# ATSAM3XxE register map
Vendor: Atmel; Series: SAM3X; File version: 0
Atmel ATSAM3XxE Microcontroller
CPU: CM3 r2p0, selectable endian, MPU, no FPU, 4 interrupt priority bits
Registers are 32-bit, read-write, reset 0x0 unless marked. A register's access mark holds for its fields unless they carry their own. Offsets are from the block's base; lines under a group give offsets from that group; [hi:lo] are bit positions; {n}, {i} and the like mark numbered series; 'fields as' and 'values as' point back to an identical list; <NAME> marks a mode.

## Memory map
0x40000000 HSMCI size 0x4000 — High Speed MultiMedia Card Interface
0x40004000 SSC size 0x4000 — Synchronous Serial Controller
0x40008000 SPI0 size 0x4000 — Serial Peripheral Interface 0
0x4000D000 MPU size 0x830 — Memory Protection Unit (MPU)
0x40080000 TC0 size 0x4000 — Timer Counter 0
0x40084000 TC1 size 0x4000 — Timer Counter 1
0x40088000 TC2 size 0x4000 — Timer Counter 2
0x4008C000 TWI0 size 0x4000 — Two-wire Interface 0
0x40090000 TWI1 size 0x4000 — Two-wire Interface 1
0x40094000 PWM size 0x4000 — Pulse Width Modulation Controller
0x40098000 USART0 size 0x4000 — Universal Synchronous Asynchronous Receiver Transmitter 0
0x4009C000 USART1 size 0x4000 — Universal Synchronous Asynchronous Receiver Transmitter 1
0x400A0000 USART2 size 0x4000 — Universal Synchronous Asynchronous Receiver Transmitter 2
0x400A4000 USART3 size 0x4000 — Universal Synchronous Asynchronous Receiver Transmitter 3
0x400AC000 UOTGHS size 0x4000 — USB On-The-Go Interface
0x400B0000 EMAC size 0x4000 — Ethernet MAC 10/100
0x400B4000 CAN0 size 0x4000 — Controller Area Network 0
0x400B8000 CAN1 size 0x4000 — Controller Area Network 1
0x400BC000 TRNG size 0x4000 — True Random Number Generator
0x400C0000 ADC size 0x4000 — Analog-to-Digital Converter
0x400C4000 DMAC size 0x4000 — DMA Controller
0x400C8000 DACC size 0x4000 — Digital-to-Analog Converter Controller
0x400E0000 SMC size 0x200 — Static Memory Controller
0x400E0400 MATRIX size 0x200 — AHB Bus Matrix
0x400E0600 PMC size 0x140 — Power Management Controller
0x400E0800 UART size 0x128 — Universal Asynchronous Receiver Transmitter
0x400E0940 CHIPID size 0x200 — Chip Identifier
0x400E0A00 EFC0 size 0x200 — Embedded Flash Controller 0
0x400E0C00 EFC1 size 0x200 — Embedded Flash Controller 1
0x400E0E00 PIOA size 0x200 — Parallel Input/Output Controller A
0x400E1000 PIOB size 0x200 — Parallel Input/Output Controller B
0x400E1200 PIOC size 0x200 — Parallel Input/Output Controller C
0x400E1400 PIOD size 0x200 — Parallel Input/Output Controller D
0x400E1A00 RSTC size 0x10 — Reset Controller
0x400E1A10 SUPC size 0x18 — Supply Controller
0x400E1A30 RTT size 0x10 — Real-time Timer
0x400E1A50 WDT size 0x10 — Watchdog Timer
0x400E1A60 RTC size 0xE8 — Real-time Clock
0x400E1A90 GPBR size 0x20 — General Purpose Backup Registers
0xE000E000 SCB blocks up to offset 0xD40 — System Control Block (SCB)
0xE000E010 SYST size 0x10 — System timer, SysTick
0xE000E100 NVIC size 0xE04 — Nested Vectored Interrupt Controller (NVIC)

## Interrupts
3 INT_Hard_Fault (SCB)
4 INT_Mem_Manage_Fault (SCB)
5 INT_Bus_Fault (SCB)
5 PMC
6 EFC0
6 INT_Usage_Fault (SCB)
7 EFC1
8 UART
11 INT_SVCall (SCB)
11 PIOA
12 PIOB
13 PIOC
14 INT_PendableSrvReq (SCB)
14 PIOD
15 INT_SysTick (SYST)
17 USART0
18 USART1
19 USART2
20 USART3
21 HSMCI
22 TWI0
23 TWI1
24 SPI0
26 SSC
27 TC0
28 TC1 (TC0)
29 TC2 (TC0)
30 TC3 (TC1)
31 TC4 (TC1)
32 TC5 (TC1)
33 TC6 (TC2)
34 TC7 (TC2)
35 TC8 (TC2)
36 PWM
37 ADC
38 DACC
39 DMAC
40 UOTGHS
41 TRNG
42 EMAC
43 CAN0
44 CAN1

## SPI0 — Serial Peripheral Interface 0
Base 0x40008000; register names take the prefix SPI0_
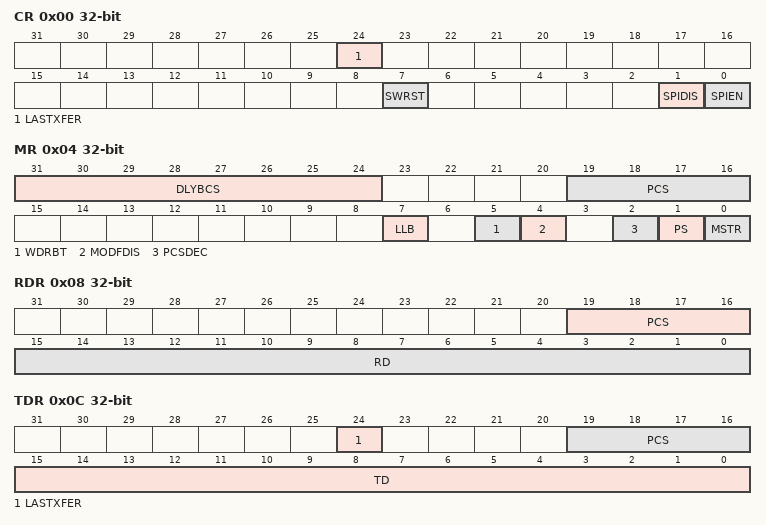
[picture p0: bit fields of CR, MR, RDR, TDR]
0x00 CR wo reset not defined — Control Register
  [24] LASTXFER — Last Transfer
  [7] SWRST — SPI Software Reset
  [1] SPIDIS — SPI Disable
  [0] SPIEN — SPI Enable
0x04 MR — Mode Register
  [31:24] DLYBCS — Delay Between Chip Selects
  [19:16] PCS — Peripheral Chip Select
  [7] LLB — Local Loopback Enable
  [5] WDRBT — Wait Data Read Before Transfer
  [4] MODFDIS — Mode Fault Detection
  [2] PCSDEC — Chip Select Decode
  [1] PS — Peripheral Select
  [0] MSTR — Master/Slave Mode
0x08 RDR ro — Receive Data Register
  [19:16] PCS — Peripheral Chip Select
  [15:0] RD — Receive Data
0x0C TDR wo reset not defined — Transmit Data Register
  [24] LASTXFER — Last Transfer
  [19:16] PCS — Peripheral Chip Select
  [15:0] TD — Transmit Data
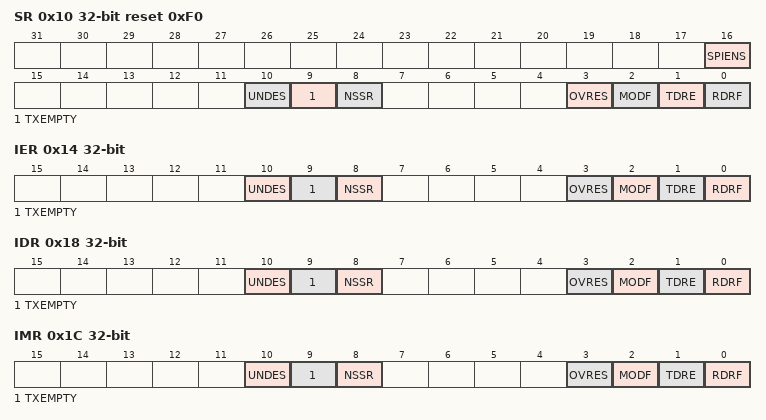
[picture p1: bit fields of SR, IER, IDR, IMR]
0x10 SR ro reset 0xF0 — Status Register
  [16] SPIENS — SPI Enable Status
  [10] UNDES — Underrun Error Status (Slave Mode Only)
  [9] TXEMPTY — Transmission Registers Empty
  [8] NSSR — NSS Rising
  [3] OVRES — Overrun Error Status
  [2] MODF — Mode Fault Error
  [1] TDRE — Transmit Data Register Empty
  [0] RDRF — Receive Data Register Full
0x14 IER wo reset not defined — Interrupt Enable Register
  [10] UNDES — Underrun Error Interrupt Enable
  [9] TXEMPTY — Transmission Registers Empty Enable
  [8] NSSR — NSS Rising Interrupt Enable
  [3] OVRES — Overrun Error Interrupt Enable
  [2] MODF — Mode Fault Error Interrupt Enable
  [1] TDRE — SPI Transmit Data Register Empty Interrupt Enable
  [0] RDRF — Receive Data Register Full Interrupt Enable
0x18 IDR wo reset not defined — Interrupt Disable Register
  [10] UNDES — Underrun Error Interrupt Disable
  [9] TXEMPTY — Transmission Registers Empty Disable
  [8] NSSR — NSS Rising Interrupt Disable
  [3] OVRES — Overrun Error Interrupt Disable
  [2] MODF — Mode Fault Error Interrupt Disable
  [1] TDRE — SPI Transmit Data Register Empty Interrupt Disable
  [0] RDRF — Receive Data Register Full Interrupt Disable
0x1C IMR ro — Interrupt Mask Register
  [10] UNDES — Underrun Error Interrupt Mask
  [9] TXEMPTY — Transmission Registers Empty Mask
  [8] NSSR — NSS Rising Interrupt Mask
  [3] OVRES — Overrun Error Interrupt Mask
  [2] MODF — Mode Fault Error Interrupt Mask
  [1] TDRE — SPI Transmit Data Register Empty Interrupt Mask
  [0] RDRF — Receive Data Register Full Interrupt Mask
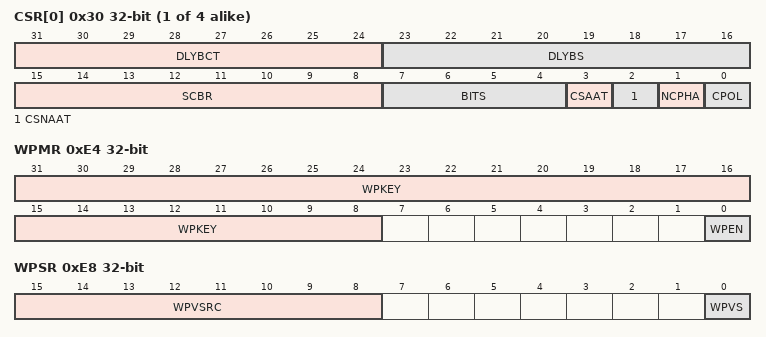
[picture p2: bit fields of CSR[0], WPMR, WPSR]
{0x30+4i} CSR[{i}] (i=0..3) reset not defined — Chip Select Register
  [31:24] DLYBCT — Delay Between Consecutive Transfers
  [23:16] DLYBS — Delay Before SPCK
  [15:8] SCBR — Serial Clock Baud Rate
  [7:4] BITS — Bits Per Transfer
    {v}={v+8}_BIT ({v+8} bits for transfer) (v=0..8)
  [3] CSAAT — Chip Select Active After Transfer
  [2] CSNAAT — Chip Select Not Active After Transfer (Ignored if CSAAT = 1)
  [1] NCPHA — Clock Phase
  [0] CPOL — Clock Polarity
0xE4 WPMR — Write Protection Control Register
  [31:8] WPKEY — Write Protect Key
    0x535049=PASSWD (Writing any other value in this field aborts the write operation of the WPEN bit.Always reads as 0.)
  [0] WPEN — Write Protect Enable
0xE8 WPSR ro — Write Protection Status Register
  [15:8] WPVSRC — Write Protection Violation Source
  [0] WPVS — Write Protection Violation Status

## Notices in the file
SAM Software Package License
Copyright (c) 2014, Atmel Corporation
All rights reserved.
Redistribution and use in source and binary forms, with or without
modification, are permitted provided that the following condition is met:
- Redistributions of source code must retain the above copyright notice,
this list of conditions and the disclaimer below.
Atmel's name may not be used to endorse or promote products derived from
this software without specific prior written permission.
DISCLAIMER:  THIS SOFTWARE IS PROVIDED BY ATMEL "AS IS" AND ANY EXPRESS OR
IMPLIED WARRANTIES, INCLUDING, BUT NOT LIMITED TO, THE IMPLIED WARRANTIES OF
MERCHANTABILITY, FITNESS FOR A PARTICULAR PURPOSE AND NON-INFRINGEMENT ARE
DISCLAIMED. IN NO EVENT SHALL ATMEL BE LIABLE FOR ANY DIRECT, INDIRECT,
INCIDENTAL, SPECIAL, EXEMPLARY, OR CONSEQUENTIAL DAMAGES (INCLUDING, BUT NOT
LIMITED TO, PROCUREMENT OF SUBSTITUTE GOODS OR SERVICES; LOSS OF USE, DATA,
OR PROFITS; OR BUSINESS INTERRUPTION) HOWEVER CAUSED AND ON ANY THEORY OF
LIABILITY, WHETHER IN CONTRACT, STRICT LIABILITY, OR TORT (INCLUDING
NEGLIGENCE OR OTHERWISE) ARISING IN ANY WAY OUT OF THE USE OF THIS SOFTWARE,
EVEN IF ADVISED OF THE POSSIBILITY OF SUCH DAMAGE.
